# RTS5918 register map
Vendor: Realtek Semiconductor Corp.; Series: RTS5918 Series; File version: 1.00
CPU: ARMV8MML r0p0, little endian, MPU, FPU, VTOR, 3 interrupt priority bits, 8 SAU regions
Registers are 32-bit, read-write, reset 0x0 unless marked. A register's access mark holds for its fields unless they carry their own. Offsets are from the block's base; [hi:lo] are bit positions; 'fields as' and 'values as' point back to an identical list.

## SPIC — SPIC Controller
Base 0x40000000
Same registers: SPIC1 0x40001000
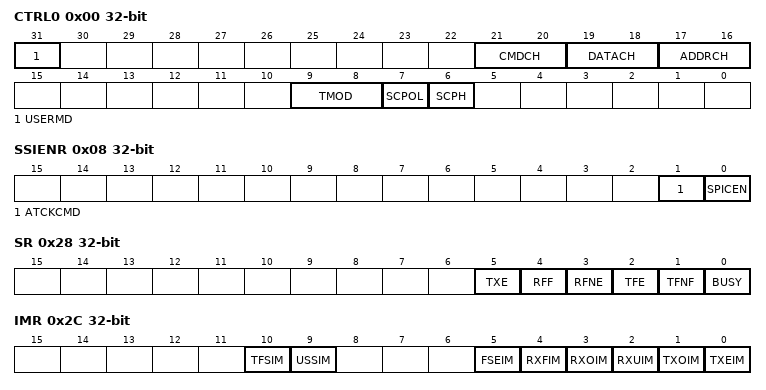
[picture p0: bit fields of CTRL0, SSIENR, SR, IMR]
0x00 CTRL0 — CONTROL REGISTER #0
  [31] USERMD — User Mode Bit
    0=AUTO_MODE; 1=USER_MODE
  [21:20] CMDCH — Channel Number of Command Phase in Transmitting or Receiving Data
    0=SINGLE (Single mode); 1=Dual mode; 2=QUAD (Quad mode); 3=OCTAL (Octal mode)
  [19:18] DATACH — Channel Number of Data in Transmitting or Receiving Data
    values as CMDCH
  [17:16] ADDRCH — Channel Number of Address Phase After Command Phase
    values as CMDCH
  [9:8] TMOD — Transfer Mode
    0=TRANSMIT (Transmit mode); other=RECEIVE (Receive mode)
  [7] SCPOL — Serial Clock Polarity
    0=LOW (INACTIVE state of serial clock is low); 1=HIGH (INACTIVE state of serial clock is high)
  [6] SCPH — Serial Clock Phase
    0=FIRST (Serial clock toggles in middle of first data bit); 1=MIDDLE (Serial clock toggles at start of first data bit)
0x04 RXNDF — NUMBER OF RX DATA FRAME REGISTER
  [23:0] NUM — Number of Rx Data Frames
0x08 SSIENR — ENABLE REGISTER
  [1] ATCKCMD — Set to enable ATCK_CMD implementation
    0=DISABLE (Disable ATCK_CMD); 1=ENABLE (Enable ATCK_CMD)
  [0] SPICEN — Set to Enable SPIC and Start User Mode Transaction
    0=DISABLE (Disable SPIC); 1=ENABLE (Enable SPIC)
0x10 SER — SELECT TARGET FLASH REGISTER
  [0] SEL — Select to SPI Flash
    0=NOT_SELECTED; 1=SELECTED
0x14 BAUDR — BAUD RATE SELECT REGISTER
  [11:0] SCKDV — Define SPI Clock Divider Value
0x18 TXFTLR — TX FIFO THRESHOLD REGISTER
0x1C RXFTLR — RECEIVE FIFO THRESHOLD LEVEL
0x20 TXFLR — TRANSMIT FIFO LEVEL REGISTER
0x24 RXFLR — RECEIVE FIFO LEVEL REGISTER
0x28 SR — STATUS REGISTER
  [5] TXE ro — Transmission error
    0=NOT_ERR (No effect); 1=ERROR (FIFO is empty and starting to transmit data to SPI Flash)
  [4] RFF ro — Receive FIFO full
    0=NOT_FULL (Receive FIFO is not full); 1=FULL (Receive FIFO is full)
  [3] RFNE ro — Receive FIFO is not empty
    0=EMPTY (FIFO is not empty in receiving mode); 1=NOT_EMPTY (FIFO is not empty in receiving mode)
  [2] TFE ro — Transmit FIFO is empty
    0=NOT_EMPTY (Transmit FIFO is not empty); 1=EMPTY (Transmit FIFO is empty)
  [1] TFNF ro — Transmit FIFO is not full
    0=FULL (Transmit FIFO is full); 1=NOT_FULL (Transmit FIFO is not full)
  [0] BUSY ro — SPIC busy flag
    0=IDLE (SPIC is idle); 1=BUSY (SPIC is busy)
0x2C IMR — Interrupt Mask Register
  [10] TFSIM — Transmit finish interrupt mask
    1=NOT_MASEKED (Transmit finish interrupt is not masked); 0=MASKED (Transmit finish interrupt is masked)
  [9] USSIM — User-mode error interrupt mask
    1=NOT_MASEKED (User-mode error interrupt is not masked); 0=MASKED (User-mode error interrupt is masked)
  [5] FSEIM — FIFO size error interrupt mask
    1=NOT_MASEKED (FIFO size error interrupt is not masked); 0=MASKED (FIFO size error interrupt is masked)
  [4] RXFIM — Receive FIFO full interrupt masked
    1=NOT_MASEKED (Receive FIFO full interrupt is not masked); 0=MASKED (Receive FIFO full interrupt is masked)
  [3] RXOIM — Receive FIFO overflow interrupt masked
    1=NOT_MASEKED (Receive FIFO overflow interrupt is not masked); 0=MASKED (Receive FIFO overflow interrupt is masked)
  [2] RXUIM — Receive FIFO underflow interrupt masked
    1=NOT_MASEKED (Receive FIFO underflow interrupt is not masked); 0=MASKED (Receive FIFO underflow interrupt is masked)
  [1] TXOIM — Transmit FIFO overflow interrupt mask
    1=NOT_MASEKED (Transmit FIFO overflow interrupt is not masked); 0=MASKED (Transmit FIFO overflow interrupt is masked)
  [0] TXEIM — Transmit FIFO empty interrupt masked
    1=NOT_MASEKED (Transmit FIFO empty interrupt is not masked); 0=MASKED (Transmit FIFO empty interrupt is masked)
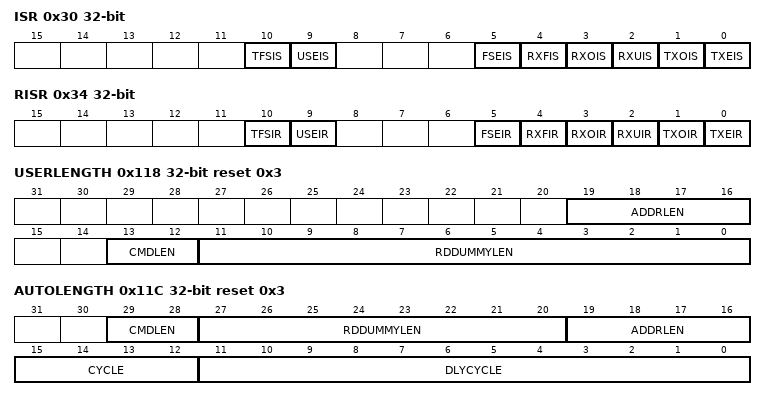
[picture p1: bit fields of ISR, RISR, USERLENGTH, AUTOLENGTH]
0x30 ISR — INTERRUPT STATUS REGISTER
  [10] TFSIS ro — Transmit finish status after masking
    0=INACTIVE (Transmit finish is not active); 1=ACTIVE (Transmit finish is active)
  [9] USEIS ro — User mode error status after masking
    0=INACTIVE (User mode error status interrupt is not active); 1=ACTIVE (User mode error status interrupt is active)
  [5] FSEIS ro — FIFO size error interrupt status after masking
    0=INACTIVE (FIFO size error interrupt is not active); 1=ACTIVE (FIFO size error interrupt is active)
  [4] RXFIS ro — Receive FIFO full interrupt status after masking
    0=INACTIVE (Receive FIFO full interrupt is not active); 1=ACTIVE (Receive FIFO full interrupt is active)
  [3] RXOIS ro — Receive FIFO overflow interrupt status after masking
    0=INACTIVE (Receive FIFO overflow interrupt is not active); 1=ACTIVE (Receive FIFO overflow interrupt is active)
  [2] RXUIS ro — Receive FIFO underflow interrupt status after masking
    0=INACTIVE (Receive FIFO underflow interrupt is not active); 1=ACTIVE (Receive FIFO underflow interrupt is active)
  [1] TXOIS ro — Transmit FIFO overflow interrupt status after masking
    0=INACTIVE (Transmit FIFO overflow interrupt is not active); 1=ACTIVE (Transmit FIFO overflow interrupt is active)
  [0] TXEIS ro — Transmit FIFO empty interrupt status after masking
    0=INACTIVE (Transmit FIFO empty interrupt is not active); 1=ACTIVE (Transmit FIFO empty interrupt is active)
0x34 RISR — RAW INTERRUPT STATUS REGISTER
  [10] TFSIR ro — Transmit Finish Status Interrupt Status Before Masking
    0=INACTIVE (Transmit Finish Status interrupt is not active); 1=ACTIVE (Transmit Finish Status interrupt is active)
  [9] USEIR ro — User_mode Error Status Interrupt Status Before Masking
    0=INACTIVE (User_mode error status interrupt is not active); 1=ACTIVE (User_mode error status interrupt is active)
  [5] FSEIR ro — FIFO Size Error Interrupt Status Before Masking
    values as ISR.FSEIS
  [4] RXFIR ro — Receive Fifo Full Interrupt Status Before Masking
    values as ISR.RXFIS
  [3] RXOIR ro — Receive Fifo Overflow Interrupt Status Before Masking
    values as ISR.RXOIS
  [2] RXUIR ro — Receive Fifo Underflow Interrupt Status Before Masking
    values as ISR.RXUIS
  [1] TXOIR ro — Transmit Fifo Overflow Interrupt Status Before Masking
    values as ISR.TXOIS
  [0] TXEIR ro — Transmit Fifo Empty Interrupt Status Before Masking
    values as ISR.TXEIS
0x38 TXOICR — TRANSMIT FIFO OVERFLOW INTERRUPT CLEAR REGISTER
0x3C RXOICR — RECEIVE FIFO OVERFLOW INTERRUPT CLEAR REGISTER
0x40 RXUICR — RECEIVE FIFO UNDERFLOW INTERRUPT CLEAR REGISTER
0x44 MSTICR — MASTER ERROR INTERRUPT CLEAR REGISTER
0x48 ICR — INTERRUPT CLEAR REGISTER
0x60 DR — DATA REGISTER
0x60 DR_BYTE (alternate view of DR) — DATA REGISTER IN BYTE
0x60 DR_HALF (alternate view of DR) — DATA REGISTER IN HALF WORD
0x60 DR_WORD (alternate view of DR) — DATA REGISTER IN WORD
0xE0 FRDCMD — FAST READ DATA COMMAND REGISTER
0x118 USERLENGTH reset 0x3 — DECIDES BYTE NUMBERS OF COMMAND, ADDRESS AND DATA PHASE TO TRANSMIT
  [19:16] ADDRLEN — Indicate Number Of Bytes In Address Phase In User Mode
  [13:12] CMDLEN — Indicate Number Of Bytes In Command Phase In User Mode
  [11:0] RDDUMMYLEN — Indicate Delay Cycles For Receiving Data In User Mode
0x11C AUTOLENGTH reset 0x3 — RX Delay Cycle and Address Size in Auto Mode
  [29:28] CMDLEN — Indicate R/W CMD Bytes In Auto Mode
  [27:20] RDDUMMYLEN — Indicate Number Of Dummy Bytes In Auto Mode after RX
  [19:16] ADDRLEN — Indicate Number Of Bytes In Address Phase In Auto Mode
  [15:12] CYCLE — Indicate Clock Cycles In Auto Mode
  [11:0] DLYCYCLE — Indicate Delay Cycles For Receiving Data In Auto Mode
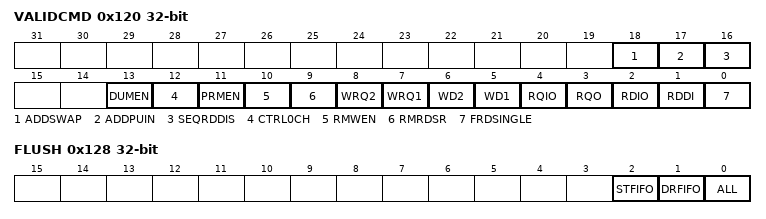
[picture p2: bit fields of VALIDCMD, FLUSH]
0x120 VALIDCMD — Valid Command Register
  [18] ADDSWAP — Enable Address Swap based on CR.FLASH_SIZE in Auto Mode
  [17] ADDPUIN — Pull in First Address to Negedge of spi_clk
  [16] SEQRDDIS — Disable Sequential R/W in Auto Mode
  [13] DUMEN — Push Dummy Byte after Pushing Address to Flash in Auto Read
  [12] CTRL0CH — CMD_CH/DATA_CH/ADDR_CH and DDR_EN Field in Auto Mode
  [11] PRMEN — Enable SPI Performance Read Mode in Auto Write
  [10] RMWEN — Remove Write Enable in Auto Write
  [9] RMRDSR — Remove Read Status Register in Auto Write
  [8] WRQ2 — Quad Address/Data Write is a Valid Command to Execute
  [7] WRQ1 — Quad Data Write is a Valid Command to Execute
  [6] WD2 — Dual Address/Data Write is a Valid Command to Execute
  [5] WD1 — Dual Data Write is a Valid Command to Execute
  [4] RQIO — Quad Address/Data Read is a Valid Command to Execute
  [3] RQO — Quad Data Read is a Valid Command to Execute
  [2] RDIO — Dual Address/Data Read is a Valid Command to Execute
  [1] RDDI — Dual Data Read is a Valid Command to Execute
  [0] FRDSINGLE — Fast Read is a Valid Command to Execute
0x128 FLUSH — FLUSH FIFO REGISTER
  [2] STFIFO — Clear All Data in the ST_FIFO
    0=DO_NOTHING; 1=FLUSH (Clear all data in the ST_FIFO)
  [1] DRFIFO — Clear All Data in the TX FIFO and RX FIFO
    0=DO_NOTHING; 1=FLUSH (Clear all data in the TX FIFO and RX FIFO)
  [0] ALL — Clear All Data In All FIFO (Include TX_FIFO, RX_FIFO and ST_FIFO)
    0=DO_NOTHING; 1=FLUSH (Clear all data in all FIFO (include TX_FIFO, RX_FIFO and ST_FIFO))
0x130 TXNDF — A NUMBER OF DATA FRAMES OF TX DATA IN USER MODE
  [23:0] NUM — Number of Rx Data Frames
0x158 GATE — CLK GATING CONTROL REGISTER
  [4] AWGATE — Auto Write Clock Gating Enable
